# GD32A72_A74x register map
File version: 1.0
CPU: CM7 r2p1, little endian, MPU, FPU, DSP, 4 interrupt priority bits
Registers are 32-bit, read-write, reset 0x0 unless marked. A register's access mark holds for its fields unless they carry their own. Offsets are from the block's base; [hi:lo] are bit positions; {n}, {i} and the like mark numbered series; 'fields as' and 'values as' point back to an identical list.

## MCMUB — Multi-core messaging unit
Base 0x49008400
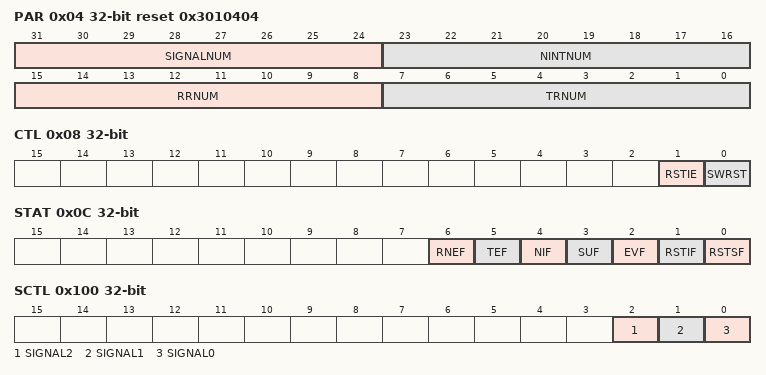
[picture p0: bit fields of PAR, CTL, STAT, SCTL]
0x04 PAR ro reset 0x3010404 — Parameter register
  [31:24] SIGNALNUM — The number of signal bits in the MCMUB_SCTL register and MCMUB_SSTAT register
  [23:16] NINTNUM — The number of normal interrupt requests available
  [15:8] RRNUM — The number of receive register
  [7:0] TRNUM — The number of transmit register
0x08 CTL wo — Control register
  [1] RSTIE — mcmub reset interrupt enable (only can be reset by system reset)
  [0] SWRST — Software reset MCMU (always read 0)
0x0C STAT access per field — Status register
  [6] RNEF ro — Receive not empty flag
  [5] TEF ro — Transmit empty flag
  [4] NIF ro — Normal interrupt flag
  [3] SUF ro — Signal update flag
  [2] EVF ro — MCMUB side event flag
  [1] RSTIF rw — MCMU reset interrupt flag
  [0] RSTSF ro — MCMU reset state flag
0x100 SCTL — Signal control register
  [2] SIGNAL2 — MCMUB to MCMUA signal2
  [1] SIGNAL1 — MCMUB to MCMUA signal1
  [0] SIGNAL0 — MCMUB to MCMUA signal0
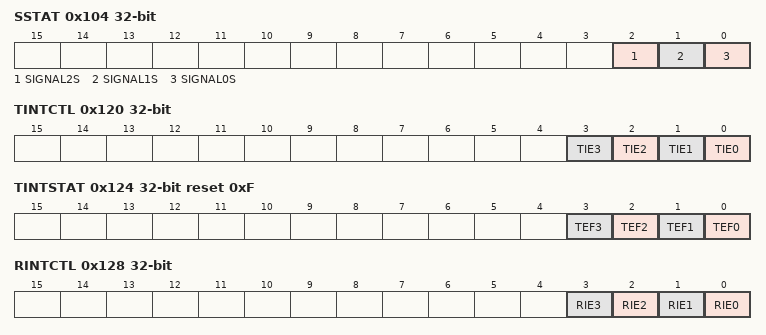
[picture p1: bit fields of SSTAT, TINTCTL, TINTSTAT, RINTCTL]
0x104 SSTAT ro — Signal status register
  [2] SIGNAL2S — MCMUA to MCMUB signal2 status
  [1] SIGNAL1S — MCMUA to MCMUB signal1 status
  [0] SIGNAL0S — MCMUA to MCMUB signal0 status
0x110 NINTEN — Normal interrupt enable register
  [0] NIE0 — Enable normal interrupt
0x114 NINTCTL — Normal interrupt control register
  [0] NIR0 — MCMUB normal interrupt request (only be cleared by MCMUA)
0x118 NINTSTAT — Normal interrupt Status register
  [0] NIF0 — MCMUB normal interrupt flag from MCMUA
0x120 TINTCTL — Transmit Interrupt Control register
  [n] TIE{n} (n=0..3) — MCMUB transmit interrupt enable {n}
0x124 TINTSTAT ro reset 0xF — Transmit Interrupt Status register
  [n] TEF{n} (n=0..3) — MCMUB transmit register {n} empty
0x128 RINTCTL — Receive Interrupt Control register
  [n] RIE{n} (n=0..3) — MCMUB receive interrupt {n} enable
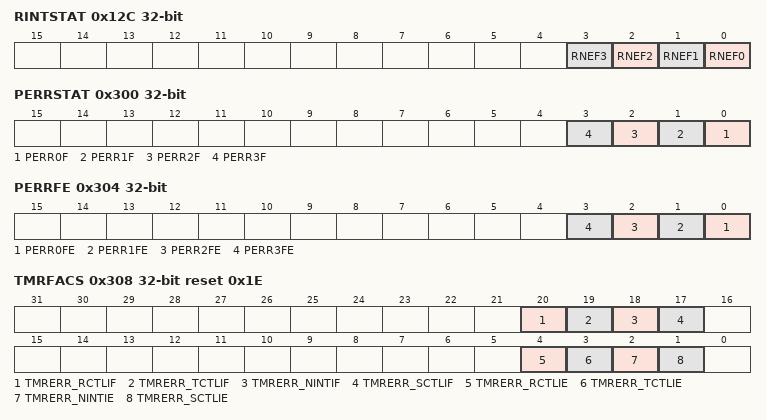
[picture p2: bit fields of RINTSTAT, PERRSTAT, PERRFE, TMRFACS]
0x12C RINTSTAT ro — Receive Interrupt Status register
  [n] RNEF{n} (n=0..3) — mcmub_rdatax register {n} is not empty
{0x200+4i} TDATA{i} wo (i=0..3) — Transmit data register {i}
  [31:0] TDATA — MCMUB Transmit Data
{0x280+4i} RDATA{i} ro (i=0..3) — Receive data register {i}
  [31:0] RDATA — MCMUB Receive Data
0x300 PERRSTAT — Parity Error Status register
  [n] PERR{n}F (n=0..3) — Transmit / receive register {n} parity check error flag
0x304 PERRFE — Parity Error fault enable register
  [n] PERR{n}FE (n=0..3) — Enable transmit /receive register {n} parity check error connection to FMU
0x308 TMRFACS reset 0x1E — TMR fault control and status register
  [20] TMRERR_RCTLIF — TMR fault flag of the receive interrupt enable bits in the receive control register of MCMUA side
  [19] TMRERR_TCTLIF — TMR fault flag of the transmit interrupt enable in the transmit control register of MCMUA side
  [18] TMRERR_NINTIF — TMR fault flag of the normal interrupt enable and request in the normal interrupt enable and control registers of MCMUA side
  [17] TMRERR_SCTLIF — TMR fault signal of MCMUA to MCMUB signals in the signal control register of MCMUA side
  [4] TMRERR_RCTLIE — Enable TMR fault alarm interrupt of the receive data interrupt enable in MCMUA_RINTCTL
  [3] TMRERR_TCTLIE — Enable TMR fault alarm interrupt of the transmit interrupt enable in MCMUA_TINTCTL
  [2] TMRERR_NINTIE — Enable TMR fault alarm interrupt of the normal interrupt enable and request in MCMUA_NINTEN and MCMUA_NINTCTL
  [1] TMRERR_SCTLIE — Enable TMR fault alarm interrupt of MCMUA to MCMUB signals in MCMUA_SCTL

## MFCOM — Multi-function communication Interface
Base 0x49003400
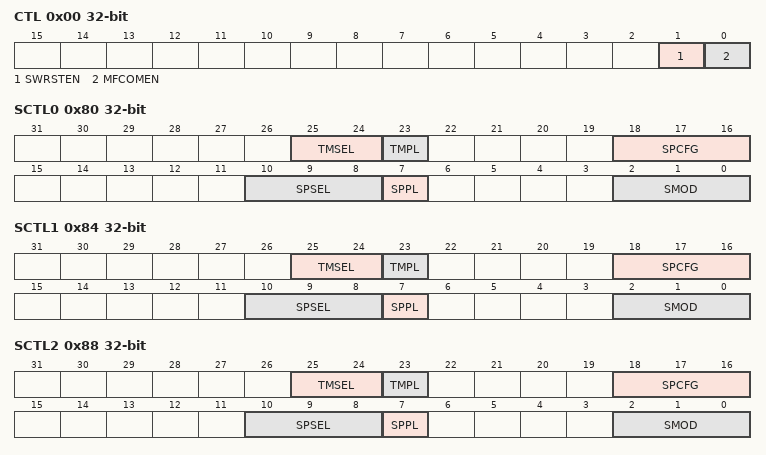
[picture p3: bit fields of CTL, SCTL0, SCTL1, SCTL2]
0x00 CTL — Control register
  [1] SWRSTEN — Software reset enable
  [0] MFCOMEN — MFCOM enable
0x04 PINDATA ro
  [7:0] PDATA — data of pins
0x08 SSTAT — Shifter status register
  [3:0] SSTAT — Shifter x status flag
0x0C SERR — Shifter error register
  [3:0] SERR — Shifter x error flags
0x10 TMSTAT — Timer status register
  [3:0] TMSTAT — Timer x status flags
0x18 SSIEN — Shifter status interrupt enable register
  [3:0] SSIEN — Shifter status interrupt enable
0x1C SEIEN — Shifter error interrupt enable register
  [3:0] SEIEN — Shifter error interrupt enable
0x20 TMSIEN — Timer status interrupt enable register
  [3:0] TMSIEN — Timer status interrupt enable
0x28 SSDMAEN — Shifter status DMA enable register
  [3:0] SSDMAEN — Shifter status DMA enable
0x80 SCTL0 — Shifter control 0 register
  [25:24] TMSEL — Timer select
  [23] TMPL — Timer polarity
  [18:16] SPCFG — Shifter pin configuration
  [10:8] SPSEL — Shifter pin select
  [7] SPPL — Shifter pin polarity
  [2:0] SMOD — Shifter mode
0x84 SCTL1 — Shifter control 1 register
  fields as SCTL0
0x88 SCTL2 — Shifter control 2 register
  [25:24] TMSEL — Timer select
  [23] TMPL — Timer polarity
  [18:16] SPCFG — Shifter pin configuration
  [10:8] SPSEL — Shifter pin select
  [7] SPPL — Shifter pin polarity
  [2:0] SMOD — shifter mode
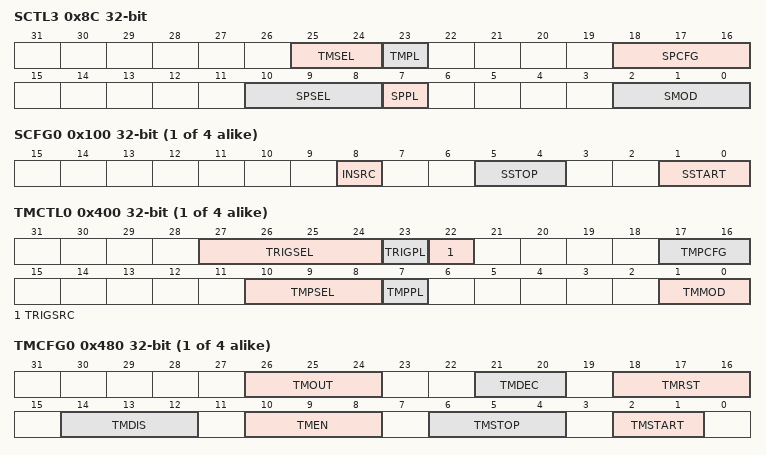
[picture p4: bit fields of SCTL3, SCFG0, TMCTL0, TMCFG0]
0x8C SCTL3 — Shifter control 3 register
  [25:24] TMSEL — timer select
  [23] TMPL — timer polarity
  [18:16] SPCFG — shifter pin configuration
  [10:8] SPSEL — shifter pin select
  [7] SPPL — shifter pin polarity
  [2:0] SMOD — shifter mode
{0x100+4i} SCFG{i} (i=0..3) — Shifter configuration {i} register
  [8] INSRC — input source
  [5:4] SSTOP — shifter stop bit
  [1:0] SSTART — shifter start bit
{0x200+4i} SBUF{i} (i=0..3) — Shifter buffer {i} register
  [31:0] SBUF — shift buffer
{0x280+4i} SBUFBIS{i} (i=0..3) — Shifter buffer {i} bit swapped register
  [31:0] SBUFBIS — shift buffer bit swapped
{0x300+4i} SBUFBYS{i} (i=0..3) — Shifter buffer {i} byte swapped register
  [31:0] SBUFBYS — shift buffer byte swapped
{0x380+4i} SBUFBBS{i} (i=0..3) — Shifter buffer {i} bit byte swapped register
  [31:0] SBUFBBS — shift buffer bit byte swapped
{0x400+4i} TMCTL{i} (i=0..3) — Timer control {i} register
  [27:24] TRIGSEL — trigger select
  [23] TRIGPL — trigger polarity
  [22] TRIGSRC — trigger source
  [17:16] TMPCFG — timer pin configuration
  [10:8] TMPSEL — timer pin select
  [7] TMPPL — timer pin polarity
  [1:0] TMMOD — timer mode
{0x480+4i} TMCFG{i} (i=0..3) — Timer configuration {i} register
  [26:24] TMOUT — timer output
  [21:20] TMDEC — timer decrement
  [18:16] TMRST — timer reset
  [14:12] TMDIS — timer disable
  [10:8] TMEN — timer enable
  [6:4] TMSTOP — timer stop bit
  [2:1] TMSTART — timer start bit
{0x500+4i} TMCMP{i} (i=0..3) — Timer compare {i} register
  [15:0] TMCVALUE — timer compare value
